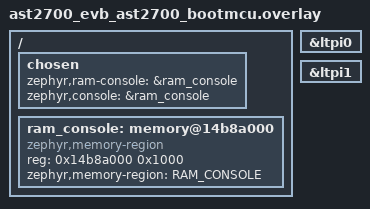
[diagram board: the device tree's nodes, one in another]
&ltpi0{
	status = "okay";
};

&ltpi1{
	status = "okay";
};

/ {
	chosen {
		zephyr,ram-console = &ram_console;
		zephyr,console = &ram_console;
	};

	ram_console: memory@14b8a000 {
		compatible = "zephyr,memory-region";
		reg = <0x14b8a000 0x1000>;
		zephyr,memory-region = "RAM_CONSOLE";
	};
};
